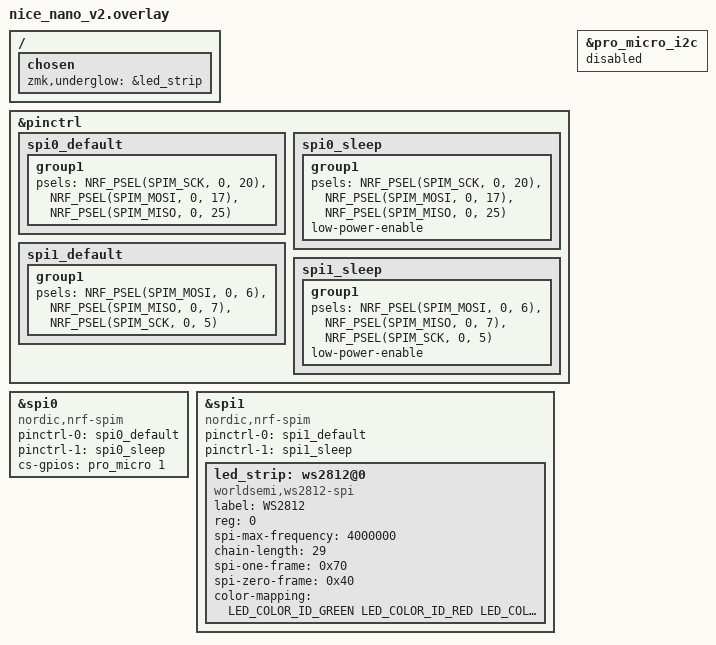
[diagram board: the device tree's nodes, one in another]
#include <dt-bindings/led/led.h>

&pinctrl {
    spi0_default: spi0_default {
		group1 {
			psels = <NRF_PSEL(SPIM_SCK, 0, 20)>,
				<NRF_PSEL(SPIM_MOSI, 0, 17)>,
				<NRF_PSEL(SPIM_MISO, 0, 25)>;
		};
	};

	spi0_sleep: spi0_sleep {
		group1 {
			psels = <NRF_PSEL(SPIM_SCK, 0, 20)>,
				<NRF_PSEL(SPIM_MOSI, 0, 17)>,
				<NRF_PSEL(SPIM_MISO, 0, 25)>;
			low-power-enable;
		};
	};

    spi1_default: spi1_default {
        group1 {
            //    mosi-pin = <6>;
            //    // Unused pins, needed for SPI definition, but not used by the ws2812 driver itself.
            //    sck-pin = <5>;
            //    miso-pin = <7>;
            psels = <NRF_PSEL(SPIM_MOSI, 0, 6)>,
                    <NRF_PSEL(SPIM_MISO, 0, 7)>,
                    <NRF_PSEL(SPIM_SCK, 0, 5)>;
        };
    };

    spi1_sleep: spi1_sleep {
        group1 {
            //    mosi-pin = <6>;
            //    // Unused pins, needed for SPI definition, but not used by the ws2812 driver itself.
            //    sck-pin = <5>;
            //    miso-pin = <7>;
            psels = <NRF_PSEL(SPIM_MOSI, 0, 6)>,
                    <NRF_PSEL(SPIM_MISO, 0, 7)>,
                    <NRF_PSEL(SPIM_SCK, 0, 5)>;
            low-power-enable;
        };
    };
};

nice_view_spi: &spi0 {
	compatible = "nordic,nrf-spim";
	pinctrl-0 = <&spi0_default>;
	pinctrl-1 = <&spi0_sleep>;
	pinctrl-names = "default", "sleep";
	cs-gpios = <&pro_micro 1 GPIO_ACTIVE_HIGH>;
};

sofle_rgb_spi: &spi1 {
    compatible = "nordic,nrf-spim";
    pinctrl-0 = <&spi1_default>;
    pinctrl-1 = <&spi1_sleep>;
    pinctrl-names = "default", "sleep";
    status = "okay";

    led_strip: ws2812@0 {
        compatible = "worldsemi,ws2812-spi";
        label = "WS2812";

        /* SPI */
        reg = <0>; /* ignored, but necessary for SPI bindings */
        spi-max-frequency = <4000000>;

        /* WS2812 */
        chain-length = <29>; /* arbitrary; change at will */
        spi-one-frame = <0x70>;
        spi-zero-frame = <0x40>;
        color-mapping = <
            LED_COLOR_ID_GREEN
            LED_COLOR_ID_RED
            LED_COLOR_ID_BLUE
        >;
    };
};

&pro_micro_i2c {
    status = "disabled";
};

/ {
    chosen {
        zmk,underglow = &led_strip;
    };
};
